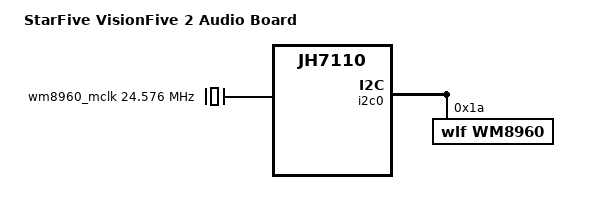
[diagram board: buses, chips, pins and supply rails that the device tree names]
// SPDX-License-Identifier: GPL-2.0 OR MIT
/*
 * Device Tree for JH7110 + Simple Audio Card
 *
 * Copyright (C) 2023 StarFive Technology Co., Ltd.
 */

/dts-v1/;
#include "jh7110-starfive-visionfive-2-v1.3b.dts"

/ {
	model = "StarFive VisionFive 2 Audio Board";
	compatible = "starfive,visionfive-2-audio", "starfive,jh7110";

	wm8960_mclk: wm8960-mclk {
		compatible = "fixed-clock";
		clock-output-names = "wm8960_mclk";
		#clock-cells = <0>;
		clock-frequency = <24576000>;
	};

	sound {
		compatible = "simple-audio-card";

		#address-cells = <1>;
		#size-cells = <0>;

		simple-audio-card,name = "Starfive-TDM-Sound-Card";
		simple-audio-card,widgets = "Microphone", "Mic Jack",
					    "Line", "Line In",
					    "Line", "Line Out",
					    "Speaker", "Speaker",
					    "Headphone", "Headphone Jack";
		simple-audio-card,routing = "Headphone Jack", "HP_L",
					    "Headphone Jack", "HP_R",
					    "Speaker", "SPK_LP",
					    "Speaker", "SPK_LN",
					    "LINPUT1", "Mic Jack",
					    "LINPUT3", "Mic Jack",
					    "RINPUT1", "Mic Jack",
					    "RINPUT2", "Mic Jack";

		simple-audio-card,dai-link@0 {
			reg = <0>;
			format = "dsp_a";
			bitclock-master = <&dailink_master>;
			frame-master = <&dailink_master>;

			cpu {
				sound-dai = <&tdm>;
			};
			dailink_master: codec {
				sound-dai = <&wm8960>;
				clocks = <&wm8960_mclk>;
			};
		};
	};
};

&i2c0 {
	wm8960: codec@1a {
		compatible = "wlf,wm8960";
		reg = <0x1a>;
		wlf,shared-lrclk;
		#sound-dai-cells = <0>;
	};
};
